# LPC5411x register map
File version: 0.3
CPU: CM4 r0p0, little endian, MPU, FPU, 3 interrupt priority bits
Registers are 32-bit, read-write, reset 0x0 unless marked. A register's access mark holds for its fields unless they carry their own. Offsets are from the block's base; [hi:lo] are bit positions; lines under a group give offsets from that group; {n}, {i} and the like mark numbered series; 'fields as' and 'values as' point back to an identical list.

## CRC — CRC engine
Base 0x40095000
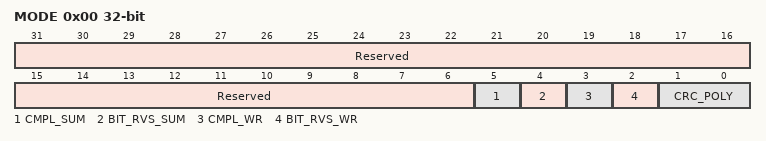
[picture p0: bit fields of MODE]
0x00 MODE — CRC mode register
  [31:6] Reserved — Always 0 when read
  [5] CMPL_SUM — CRC sum complement: 1= 1s complement for CRC_SUM 0=No 1s complement for CRC_SUM
  [4] BIT_RVS_SUM — CRC sum bit order: 1= Bit order reverse for CRC_SUM 0= No bit order reverse for CRC_SUM
  [3] CMPL_WR — Data complement: 1= 1s complement for CRC_WR_DATA 0= No 1s complement for CRC_WR_DATA
  [2] BIT_RVS_WR — Data bit order: 1= Bit order reverse for CRC_WR_DATA (per byte) 0= No bit order reverse for CRC_WR_DATA (per byte)
  [1:0] CRC_POLY — CRC polynom: 1X= CRC-32 polynomial 01= CRC-16 polynomial 00= CRC-CCITT polynomial
0x04 SEED reset 0xFFFF — CRC seed register
  [31:0] CRC_SEED — A write access to this register will load CRC seed value to CRC_SUM register with selected bit order and 1s complement pre-processes. A write access to this register will overrule the CRC calculation in progresses.
0x08 SUM ro reset 0xFFFF — CRC checksum register
  [31:0] CRC_SUM — The most recent CRC sum can be read through this register with selected bit order and 1s complement post-processes.
0x08 WR_DATA wo reset not defined — CRC data register
  [31:0] CRC_WR_DATA — Data written to this register will be taken to perform CRC calculation with selected bit order and 1s complement pre-process. Any write size 8, 16 or 32-bit are allowed and accept back-to-back transactions.

## MAILBOX
Base 0x4008B000
0x00 IRQ0 — Interrupt request register for the Cortex-M0+ CPU.
  [31:0] INTREQ — If any bit is set, an interrupt request is sent to the Cortex-M0+ interrupt controller.
0x04 IRQ0SET wo reset not defined — Set bits in IRQ0
  [31:0] INTREQSET — Writing 1 sets the corresponding bit in the IRQ0 register.
0x08 IRQ0CLR wo reset not defined — Clear bits in IRQ0
  [31:0] INTREQCLR — Writing 1 clears the corresponding bit in the IRQ0 register.
0x10 IRQ1 — Interrupt request register for the Cortex M4 CPU.
  fields as IRQ0
0x14 IRQ1SET wo reset not defined — Set bits in IRQ1
  [31:0] INTREQSET — Writing 1 sets the corresponding bit in the IRQ1 register.
0x18 IRQ1CLR wo reset not defined — Clear bits in IRQ1
  [31:0] INTREQCLR — Writing 1 clears the corresponding bit in the IRQ1 register.
0xF8 MUTEX reset 0x1 — Mutual exclusion register
  [0] EX — Cleared when read, set when written. See usage description above.

## GINT0 — Group GPIO input interrupt 0
Base 0x40002000
Same registers: GINT1 0x40003000
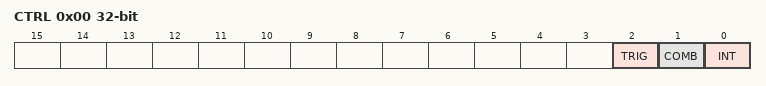
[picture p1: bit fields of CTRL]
0x00 CTRL — GPIO grouped interrupt control register
  [2] TRIG — Group interrupt trigger
    0=EDGE_TRIGGERED; 1=LEVEL_TRIGGERED
  [1] COMB — Combine enabled inputs for group interrupt
    0=OR (Or. OR functionality: A grouped interrupt is generated when any one of the enabled inputs is active (based on its programmed polarity).); 1=AND (And. AND functionality: An interrupt is generated when all enabled bits are active (based on their programmed polarity).)
  [0] INT — Group interrupt status. This bit is cleared by writing a one to it. Writing zero has no effect.
    0=NO_REQUEST (No request. No interrupt request is pending.); 1=REQUEST_ACTIVE (Request active. Interrupt request is active.)
{0x20+4i} PORT_POL{i} (i=0..2) reset 0xFFFFFFFF — GPIO grouped interrupt port 0 polarity register
  [31:0] POL — Configure pin polarity of port m pins for group interrupt. Bit n corresponds to pin PIOm_n of port m. 0 = the pin is active LOW. If the level on this pin is LOW, the pin contributes to the group interrupt. 1 = the pin is active HIGH. If the level on this pin is HIGH, the pin contributes to the group interrupt.
{0x40+4i} PORT_ENA{i} (i=0..2) — GPIO grouped interrupt port 0 enable register
  [31:0] ENA — Enable port 0 pin for group interrupt. Bit n corresponds to pin Pm_n of port m. 0 = the port 0 pin is disabled and does not contribute to the grouped interrupt. 1 = the port 0 pin is enabled and contributes to the grouped interrupt.
